# AST1080 register map
File version: 1.0
CPU: CM4 r0p1, little endian, MPU, FPU, 4 interrupt priority bits, 256 interrupts
Registers are 32-bit, read-write, reset 0x0 unless marked. A register's access mark holds for its fields unless they carry their own. Offsets are from the block's base; [hi:lo] are bit positions.

## vic
Base 0x74130000
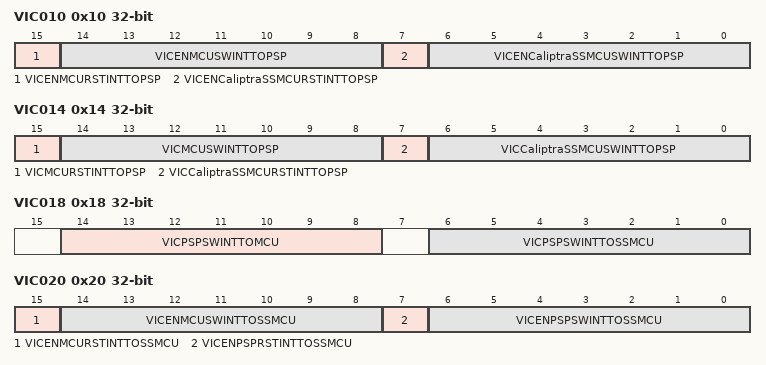
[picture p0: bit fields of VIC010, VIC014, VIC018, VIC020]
0x10 VIC010 — PSP Software Interrupt Enable
  [15] VICENMCURSTINTTOPSP, [14:8] VICENMCUSWINTTOPSP, [7] VICENCaliptraSSMCURSTINTTOPSP, [6:0] VICENCaliptraSSMCUSWINTTOPSP
0x14 VIC014 — PSP Software Interrupt Status
  [15] VICMCURSTINTTOPSP ro, [14:8] VICMCUSWINTTOPSP ro, [7] VICCaliptraSSMCURSTINTTOPSP ro, [6:0] VICCaliptraSSMCUSWINTTOPSP ro
0x18 VIC018 — PSP Software Interrupt Set
  [14:8] VICPSPSWINTTOMCU, [6:0] VICPSPSWINTTOSSMCU
0x20 VIC020 — Caliptra SSMCU Software Interrupt Enable
  [15] VICENMCURSTINTTOSSMCU, [14:8] VICENMCUSWINTTOSSMCU, [7] VICENPSPRSTINTTOSSMCU, [6:0] VICENPSPSWINTTOSSMCU
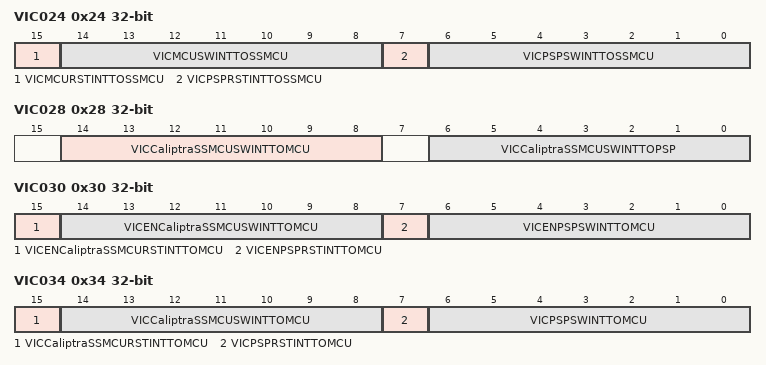
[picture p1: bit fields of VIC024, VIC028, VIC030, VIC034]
0x24 VIC024 — Caliptra SSMCU Software Interrupt Status
  [15] VICMCURSTINTTOSSMCU ro, [14:8] VICMCUSWINTTOSSMCU ro, [7] VICPSPRSTINTTOSSMCU ro, [6:0] VICPSPSWINTTOSSMCU ro
0x28 VIC028 — Caliptra SSMCU Software Interrupt Set
  [14:8] VICCaliptraSSMCUSWINTTOMCU, [6:0] VICCaliptraSSMCUSWINTTOPSP
0x30 VIC030 — MCU Software Interrupt Enable
  [15] VICENCaliptraSSMCURSTINTTOMCU, [14:8] VICENCaliptraSSMCUSWINTTOMCU, [7] VICENPSPRSTINTTOMCU, [6:0] VICENPSPSWINTTOMCU
0x34 VIC034 — MCU Software Interrupt Status
  [15] VICCaliptraSSMCURSTINTTOMCU ro, [14:8] VICCaliptraSSMCUSWINTTOMCU ro, [7] VICPSPRSTINTTOMCU ro, [6:0] VICPSPSWINTTOMCU ro
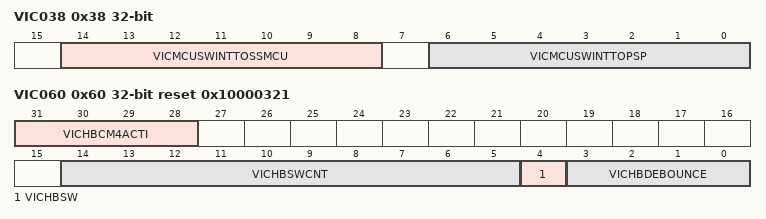
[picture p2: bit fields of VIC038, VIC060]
0x38 VIC038 — MCU Software Interrupt Set
  [14:8] VICMCUSWINTTOSSMCU, [6:0] VICMCUSWINTTOPSP
0x40 VIC040 — Register Protection
  [13:0] VICINTREGPROT
0x44 VIC044 — External Master ID
  [5:0] VICSIRQEXTMASTER
0x60 VIC060 reset 0x10000321 — HeartBeat Control
  [31:28] VICHBCM4ACTI, [14:5] VICHBSWCNT, [4] VICHBSW, [3:0] VICHBDEBOUNCE
0x64 VIC064 — HeartBeat Output Enable
  [0] VICHBOE
0x80 VIC080 — MCU Interrupt Raw 0
  [31:0] VICMCUINTRSRC0 ro
0x84 VIC084 — MCU Interrupt Raw 1
  [31:0] VICMCUINTRSRC1 ro
0x88 VIC088 — MCU Interrupt Raw 2
  [31:0] VICMCUINTRSRC2 ro
0x8C VIC08C — MCU Interrupt Raw 3
  [31:0] VICMCUINTRSRC3 ro
0x90 VIC090 — MCU Interrupt Raw 4
  [31:0] VICMCUINTRSRC4 ro
0x94 VIC094 — MCU Interrupt Raw 5
  [31:0] VICMCUINTRSRC5 ro
0x200 VIC200 — Int Routing Select 0
  [31:0] VICSIRQCSEL0
0x204 VIC204 — Int Routing Select 1
  [31:0] VICSIRQCSEL1
0x208 VIC208 — Int Routing Select 2
  [31:0] VICSIRQCSEL2
0x20C VIC20C — Int Routing Select 3
  [31:0] VICSIRQCSEL3
0x210 VIC210 — Int Routing Select 4
  [31:0] VICSIRQCSEL4
0x214 VIC214 — Int Routing Select 5
  [31:0] VICSIRQCSEL5
0x218 VIC218 — Int Routing Select 6
  [15:0] VICSIRQCSEL6
0x300 VIC300 — Int Routing Select2 0
  [31:0] VICSIRQCSEL20
0x304 VIC304 — Int Routing Select2 1
  [31:0] VICSIRQCSEL21
0x308 VIC308 — Int Routing Select2 2
  [31:0] VICSIRQCSEL22
0x30C VIC30C — Int Routing Select2 3
  [31:0] VICSIRQCSEL23
0x310 VIC310 — Int Routing Select2 4
  [31:0] VICSIRQCSEL24
0x314 VIC314 — Int Routing Select2 5
  [31:0] VICSIRQCSEL25
0x318 VIC318 — Int Routing Select2 6
  [15:0] VICSIRQCSEL26
0x400 VIC400 — Int Routing Select3 0
  [31:0] VICSIRQCSEL30
0x404 VIC404 — Int Routing Select3 1
  [31:0] VICSIRQCSEL31
0x408 VIC408 — Int Routing Select3 2
  [31:0] VICSIRQCSEL32
0x40C VIC40C — Int Routing Select3 3
  [31:0] VICSIRQCSEL33
0x410 VIC410 — Int Routing Select3 4
  [31:0] VICSIRQCSEL34
0x414 VIC414 — Int Routing Select3 5
  [31:0] VICSIRQCSEL35
0x418 VIC418 — Int Routing Select3 6
  [15:0] VICSIRQCSEL36
0x500 VIC500 — Reset INTC Select
  [5:0] VICRSTINTCSEL
0x800 VIC800 — MCU Interrupt Event 0
  [31:0] VICMCUINTREVT0
0x804 VIC804 — MCU Interrupt Event 1
  [31:0] VICMCUINTREVT1
0x808 VIC808 — MCU Interrupt Event 2
  [31:0] VICMCUINTREVT2
0x80C VIC80C — MCU Interrupt Event 3
  [31:0] VICMCUINTREVT3
0x810 VIC810 — MCU Interrupt Event 4
  [31:0] VICMCUINTREVT4
0x814 VIC814 — MCU Interrupt Event 5
  [31:0] VICMCUINTREVT5
0x818 VIC818 — MCU Interrupt Event 6
  [31:0] VICMCUINTREVT6
0x81C VIC81C — MCU Interrupt Event 7
  [15:0] VICMCUINTREVT7
0x880 VIC880 — MCU Interrupt Enable 0
  [31:0] VICMCUINTREN0
0x884 VIC884 — MCU Interrupt Enable 1
  [31:0] VICMCUINTREN1
0x888 VIC888 — MCU Interrupt Enable 2
  [31:0] VICMCUINTREN2
0x88C VIC88C — MCU Interrupt Enable 3
  [31:0] VICMCUINTREN3
0x890 VIC890 — MCU Interrupt Enable 4
  [31:0] VICMCUINTREN4
0x894 VIC894 — MCU Interrupt Enable 5
  [31:0] VICMCUINTREN5
0x898 VIC898 — MCU Interrupt Enable 6
  [31:0] VICMCUINTREN6
0x89C VIC89C — MCU Interrupt Enable 7
  [15:0] VICMCUINTREN7
